# RE01_1500KB register map
Vendor: Renesas Electronics Corporation; Series: RE01_1500KB; File version: 1.20
CPU: CM0PLUS r0p1, little endian, MPU, no FPU, VTOR, 2 interrupt priority bits
Registers are 8-bit, read-write, reset 0x0 unless marked. A register's access mark holds for its fields unless they carry their own. Offsets are from the block's base; [hi:lo] are bit positions; 'fields as' and 'values as' point back to an identical list.

## ACMP — Analog Comparator
Base 0x40085000
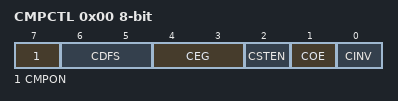
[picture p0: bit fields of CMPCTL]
0x00 CMPCTL — Comparator Control Register
  [7] CMPON — Comparator operation control
    0=Operation stopped; 1=Operation enabled
  [6:5] CDFS — Noise filter selection
    0=Noise filter not used; 1=Noise filter sampling frequency is 2^3/PCLKB; 2=Noise filter sampling frequency is 2^4/PCLKB; 3=Noise filter sampling frequency is 2^5/PCLKB
  [4:3] CEG — Selection of valid edge (Edge selector)
    0=No edge selection; 1=Rising edge selection; 2=Falling edge selection; 3=Both-edge selection
  [2] CSTEN — Interrupt Select
    0=Output via the Edge selector; 1=Direct output
  [1] COE — Comparator output enable
    0=Comparator output disabled (the output signal is low level); 1=Comparator output enabled
  [0] CINV — Comparator output polarity selection
    0=Comparator output not inverted; 1=Comparator output inverted
0x04 CMPSEL0 — Comparator Input Select Register
  [0] CMPSEL — Comparator input selection
0x08 CMPSEL1 — Comparator Reference Voltage Select Register
  [0] CVRS — Reference voltage selection
0x0C CMPMON ro — Comparator Output Monitor Register
  [0] CMPMON — Comparator output monitor
    0=Comparator output Low; 1=Comparator output High
0x10 CMPIOC
  [0] CPOE — Comparator output selection
    0=VCOUT pin output of the comparator is disabled (the output signal is low level); 1=VCOUT pin output of the comparator is enabled

## BUS — BUS Control
Base 0x40004000
0x08 BUSMCNTSYS 16-bit — Master Bus Control Register SYS
  [15] IERES — Ignore Error Responses
    0=Bus error will be reported; 1=Bus error will not be reported
0x0C BUSMCNTDMA 16-bit — Master Bus Control Register DMA
  fields as BUSMCNTSYS
0x820 BUS3ERRADD 32-bit ro — Bus Error Address Register 3
  [31:0] BERAD — Bus Error AddressWhen a bus error occurs, It stores an error address.
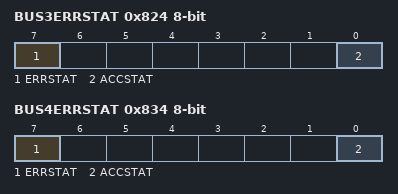
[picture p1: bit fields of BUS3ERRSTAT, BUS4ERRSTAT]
0x824 BUS3ERRSTAT ro — Bus Error Status Register 3
  [7] ERRSTAT — Bus Error StatusWhen bus error assert, error flag occurs.
    0=No bus error occurred; 1=Bus error occurred
  [0] ACCSTAT — Error access statusThe status at the time of the error
    0=Read access; 1=Write Access
0x830 BUS4ERRADD 32-bit ro — Bus Error Address Register 4
  fields as BUS3ERRADD
0x834 BUS4ERRSTAT ro — Bus Error Status Register 4
  fields as BUS3ERRSTAT

## CAC — Clock Frequency Accuracy Measurement Circuit
Base 0x40044600
0x00 CACR0 — CAC Control Register 0
  [0] CFME — Clock Frequency Measurement Enable.
    0=Disable; 1=Enable
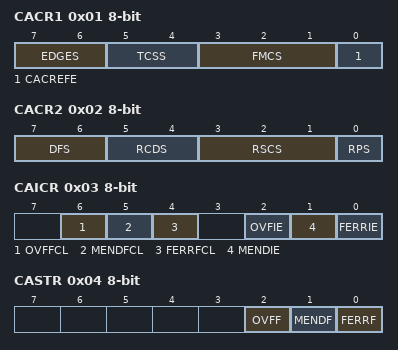
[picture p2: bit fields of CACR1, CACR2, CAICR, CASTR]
0x01 CACR1 — CAC Control Register 1
  [7:6] EDGES — Valid Edge Select
    0=Rising edge; 1=Falling edge; 2=Both rising and falling edges; 3=Setting prohibited
  [5:4] TCSS — Measurement Target Clock Frequency Division Ratio Select
    0=No division; 1=x 1/4 clock; 2=x 1/8 clock; 3=x 1/32 clock
  [3:1] FMCS — Measurement Target Clock Select
    0=Main clock; 1=Sub-clock; 2=HOCO clock; 3=LOCO clock; 4=IWDTCLK clock; 5=Peripheral module clock(PCLKB); 6=MOCO clock; 7=CCC clock
  [0] CACREFE — CACREF Pin Input Enable
    0=Disable; 1=Enable
0x02 CACR2 — CAC Control Register 2
  [7:6] DFS — Digital Filter Selection
    0=Digital filtering is disabled; 1=The sampling clock for the digital filter is the frequency measuring clock; 2=The sampling clock for the digital filter is the frequency measuring clock divided by 4; 3=The sampling clock for the digital filter is the frequency measuring clock divided by 16
  [5:4] RCDS — Measurement Reference Clock Frequency Division Ratio Select
    0=1/32 clock; 1=1/128 clock; 2=1/1024 clock; 3=1/8192 clock
  [3:1] RSCS — Measurement Reference Clock Select
    values as CACR1.FMCS
  [0] RPS — Reference Signal Select
    0=CACREF pin input; 1=Internal clock (internally generated signal)
0x03 CAICR — CAC Interrupt Control Register
  [6] OVFFCL — OVFF Clear
    0=No effect on operations; 1=Clears the OVFF flag
  [5] MENDFCL — MENDF Clear
    0=No effect on operations; 1=Clears the MENDF flag
  [4] FERRFCL — FERRF Clear
    0=No effect on operations; 1=Clears the FERRF flag
  [2] OVFIE — Overflow Interrupt Request Enable
    0=Disable; 1=Enable
  [1] MENDIE — Measurement End Interrupt Request Enable
    0=Disable; 1=Enable
  [0] FERRIE — Frequency Error Interrupt Request Enable
    0=Disable; 1=Enable
0x04 CASTR — CAC Status Register
  [2] OVFF ro — Counter Overflow Flag
    0=The counter has not overflowed; 1=The counter has overflowed
  [1] MENDF ro — Measurement End Flag
    0=Measurement is in progress; 1=Measurement has ended
  [0] FERRF ro — Frequency Error Flag
    0=The clock frequency is within the range corresponding to the settings; 1=The clock frequency has deviated beyond the range corresponding to the settings (frequency error)
0x06 CAULVR 16-bit — CAC Upper-Limit Value Setting Register
  [15:0] CAULVR — CAULVR is a 16-bit readable/writable register that stores the upper-limit value of the frequency.
0x08 CALLVR 16-bit — CAC Lower-Limit Value Setting Register
  [15:0] CALLVR — CALLVR is a 16-bit readable/writable register that stores the lower-limit value of the frequency.
0x0A CACNTBR 16-bit ro — CAC Counter Buffer Register
  [15:0] CACNTBR — CACNTBR is a 16-bit read-only register that retains the counter value at the time a valid reference signal edge is input
